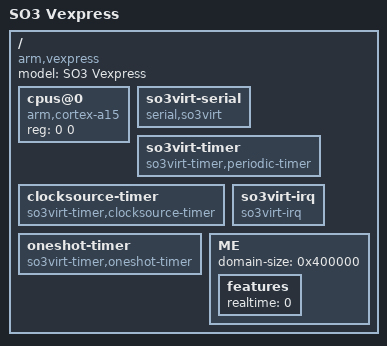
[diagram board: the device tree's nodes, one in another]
/dts-v1/;
/include/ "skeleton.dtsi"
/ {
 model = "SO3 Vexpress";
 compatible = "arm,vexpress";
 cpus@0 {
  device_type = "cpu";
  compatible = "arm,cortex-a15";
  reg = <0 0>;
 };
 so3virt-serial {
  compatible = "serial,so3virt";
  status = "ok";
 };
 so3virt-timer {
  compatible = "so3virt-timer,periodic-timer";
  status = "ok";
 };
 clocksource-timer {
  compatible = "so3virt-timer,clocksource-timer";
  status = "ok";
 };
 oneshot-timer {
  compatible ="so3virt-timer,oneshot-timer";
  status = "ok";
 };
 so3virt-irq {
  compatible = "so3virt-irq";
  status = "ok";
 };
 ME: ME {
  domain-size = <0x400000>;
  features {
   realtime = <0>;
  };
 };
};
